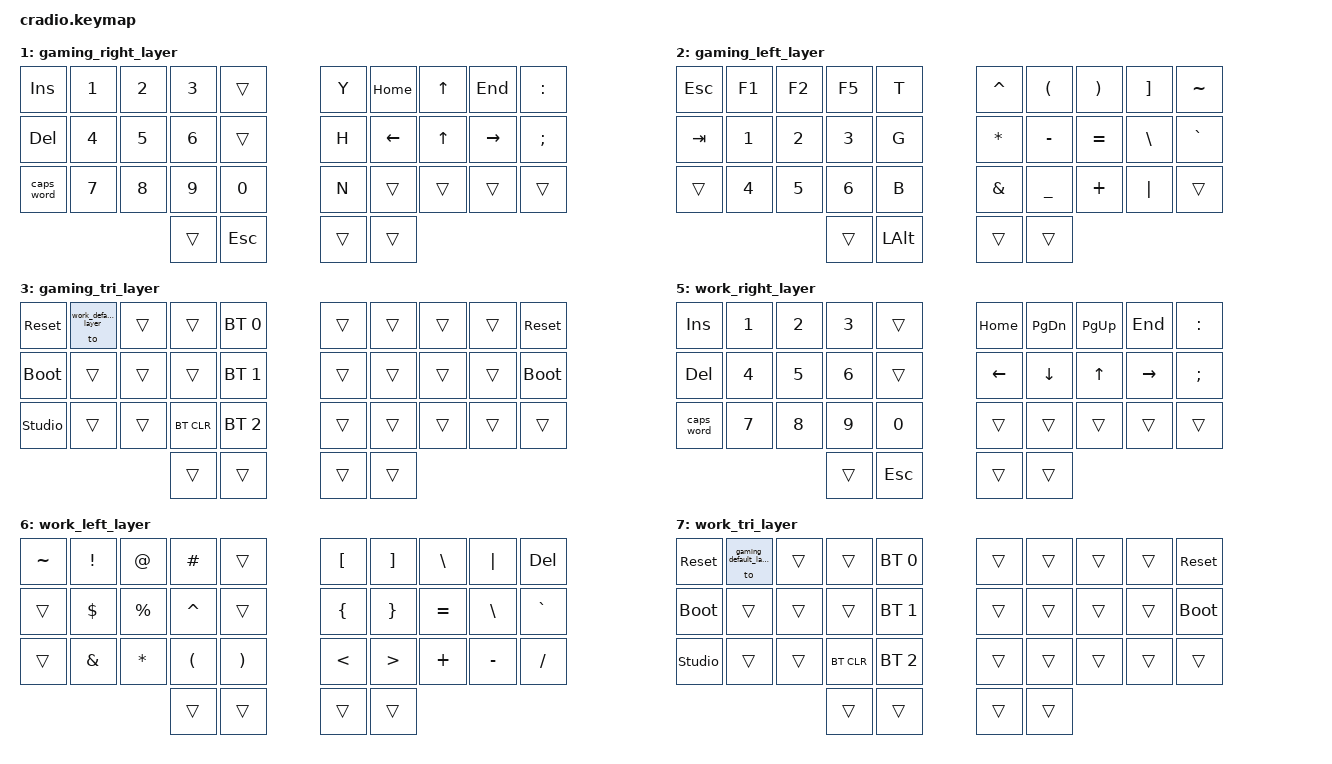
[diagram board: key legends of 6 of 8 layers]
// Copyright (c) 2022 The ZMK Contributors
// SPDX-License-Identifier: MIT

#include <behaviors.dtsi>
#include <dt-bindings/zmk/keys.h>
#include <dt-bindings/zmk/bt.h>

//defile layers for gaming and work
#define gaming_default_layer   0
#define gaming_right_layer     1
#define gaming_left_layer      2
#define gaming_tri_layer       3
#define work_default_layer     4
#define work_right_layer       5
#define work_left_layer        6
#define work_tri_layer         7

// Home row mods macro
#define HRML(k1,k2,k3,k4) &ht LSHFT k1  &ht LALT k2  &ht LCTRL k3  &ht LGUI k4
#define HRMR(k1,k2,k3,k4) &ht RGUI k1  &ht RCTRL k2  &ht RALT k3  &ht RSHFT k4

/ {
    behaviors {
        ht: hold_tap {
            compatible = "zmk,behavior-hold-tap";
            #binding-cells = <2>;
            flavor = "tap-preferred";
            tapping-term-ms = <220>;
            quick-tap-ms = <150>;
            require-prior-idle-ms = <100>;
            bindings = <&kp>, <&kp>;
        };
    };

    conditional_layers {
        compatible = "zmk,conditional-layers";
        gaming_tri_layer {
            if-layers = <gaming_right_layer gaming_left_layer>;
            then-layer = <gaming_tri_layer>;
        };
        work_tri_layer {
            if-layers = <work_right_layer work_left_layer>;
            then-layer = <work_tri_layer>;
        };
    };

    keymap {
        compatible = "zmk,keymap";
        gaming_default_layer {
            bindings = <
        //╭──────────┬──────────┬──────────┬──────────┬──────────╮   ╭──────────┬──────────┬──────────┬──────────┬──────────╮
        //│  tab     │  Q       │  W       │  E       │  R       │   │  Y       │  U       │  I       │  O       │  P       │
            &kp TAB   &kp Q      &kp W      &kp E      &kp R           &kp Y      &kp U      &kp I      &kp O      &kp P
        //├──────────┼──────────┼──────────┼──────────┼──────────┤   ├──────────┼──────────┼──────────┼──────────┼──────────┤
        //│  SHIFT   │    A     │  S       │  D       │  F       │   │  H       │  J       │  K       │  L       │ ' "      |
            &kp LSHFT   &kp  A     &kp S      &kp D     &kp F            &kp H      HRMR(J,        K,         L,        SQT)
        //├──────────┼──────────┼──────────┼──────────┼──────────┤   ├──────────┼──────────┼──────────┼──────────┼──────────┤
        //│  CTRL    │  Z       │  X       │ C        │  V       │   │  N       │  M       │ , <      │ . >      │ / ?      
            &kp RCTRL   &kp Z      &kp X      &kp C      &kp V           &kp N      &kp M   &kp COMMA   &kp DOT   &kp FSLH
        //╰──────────┴──────────┴──────────┼──────────┼──────────┤   ├──────────┼──────────┼──────────┴──────────┴──────────╯
                            &lt gaming_left_layer TAB   &kp SPACE     &kp ENTER  &lt gaming_right_layer BSPC
        //                                 ╰──────────┴──────────╯   ╰──────────┴──────────╯
            >;
        };

        gaming_right_layer {
            bindings = <
        //╭──────────┬──────────┬──────────┬──────────┬──────────╮   ╭──────────┬──────────┬──────────┬──────────┬──────────╮
        //│ INSERT   │  1       │  2       │  3       │          │   │ Y        │ HOME     │  UP      │ END      │  :       │
            &kp INS    &kp N1     &kp N2     &kp N3     &trans         &kp Y     &kp HOME    &kp UP     &kp END    &kp COLON
        //├──────────┼──────────┼──────────┼──────────┼──────────┤   ├──────────┼──────────┼──────────┼──────────┼──────────┤
        //│ DELETE   │  4       │  5       │  6       │          │   │ H        │ LEFT     │ DOWN     │ RIGHT    │  ;       │
            &kp DEL    &kp N4     &kp N5     &kp N6     &trans         &kp H      &kp LEFT   &kp UP     &kp RIGHT   &kp SEMI
        //├──────────┼──────────┼──────────┼──────────┼──────────┤   ├──────────┼──────────┼──────────┼──────────┼──────────┤
        //│ CAPS     │  7       │  8       │  9       │  0       │   │  N        │          │          │          │          │
           &caps_word  &kp N7     &kp N8     &kp N9     &kp N0         &kp N     &trans     &trans     &trans     &trans
        //╰──────────┴──────────┴──────────┼──────────┼──────────┤   ├──────────┼──────────┼──────────┴──────────┴──────────╯
                                             &trans     &kp ESC        &trans     &trans
        //                                 ╰──────────┴──────────╯   ╰──────────┴──────────╯
            >;
        };

        gaming_left_layer {
            bindings = <
        //╭──────────┬──────────┬──────────┬──────────┬──────────╮   ╭──────────┬──────────┬──────────┬──────────┬──────────╮
        //│     ESC  │  F1      │  F2      │  F5      │    T     │   │  ^       │  (       │  )       │  ]       │  ~       │
            &kp ESC     &kp F1     &kp F2    &kp F5      &kp T         &kp CARET  &kp LPAR   &kp RPAR   &kp RBKT   &kp TILDE
        //├──────────┼──────────┼──────────┼──────────┼──────────┤   ├──────────┼──────────┼──────────┼──────────┼──────────┤
        //│   tab    │  1       │  2       │  3       │  G       │   │  *       │  -       │  =       │  \       │  `       │
            &kp TAB     &kp N1     &kp N2     &kp N3      &kp G          &kp ASTRK  &kp MINUS  &kp EQUAL  &kp BSLH &kp GRAVE
        //├──────────┼──────────┼──────────┼──────────┼──────────┤   ├──────────┼──────────┼──────────┼──────────┼──────────┤
        //│          │    4     │   5      │    6     │   B      │   │  &       │  _       │  +       │  │       │          │
            &trans     &kp N4     &kp N5     &kp N6     &kp B         &kp AMPS   &kp UNDER  &kp PLUS   &kp PIPE   &trans
        //╰──────────┴──────────┴──────────┼──────────┼──────────┤   ├──────────┼──────────┼──────────┴──────────┴──────────╯
                                             &trans     &kp LALT        &trans     &trans
        //                                 ╰──────────┴──────────╯   ╰──────────┴──────────╯
            >;
        };

        gaming_tri_layer {
            bindings = <
        //╭──────────┬──────────┬──────────┬──────────┬──────────╮   ╭──────────┬──────────┬──────────┬──────────┬──────────╮
        //│ RESET    │          │          │          │PROFILE 0 │   │          │          │          │          │  RESET   │
           &sys_reset &to work_default_layer      &trans     &trans    &bt BT_SEL 0    &trans     &trans     &trans     &trans    &sys_reset
        //├──────────┼──────────┼──────────┼──────────┼──────────┤   ├──────────┼──────────┼──────────┼──────────┼──────────┤
        //│BOOTLOADER│          │          │          │PROFILE 1 │   │          │          │          │          │BOOTLOADER│
          &bootloader  &trans     &trans     &trans    &bt BT_SEL 1    &trans     &trans     &trans     &trans    &bootloader
        //├──────────┼──────────┼──────────┼──────────┼──────────┤   ├──────────┼──────────┼──────────┼──────────┼──────────┤
        //│          │          │          │ CLEAR BT │PROFILE 2 │   │          │          │          │          │          │
        &studio_unlock &trans     &trans    &bt BT_CLR &bt BT_SEL 2    &trans     &trans     &trans     &trans     &trans
        //╰──────────┴──────────┴──────────┼──────────┼──────────┤   ├──────────┼──────────┼──────────┴──────────┴──────────╯
                                             &trans     &trans         &trans     &trans
        //                                 ╰──────────┴──────────╯   ╰──────────┴──────────╯
            >;
        };
//////////////////////////////////////////////////////////////////////////////////////////////////////////////////////////////
        work_default_layer {
            bindings = <
        //╭──────────┬──────────┬──────────┬──────────┬──────────╮   ╭──────────┬──────────┬──────────┬──────────┬──────────╮
        //│  Q       │  W       │  E       │  R       │  T       │   │  Y       │  U       │  I       │  O       │  P       │
            &kp Q      &kp W      &kp E      &kp R      &kp T          &kp Y      &kp U      &kp I      &kp O      &kp P
        //├──────────┼──────────┼──────────┼──────────┼──────────┤   ├──────────┼──────────┼──────────┼──────────┼──────────┤
        //│  A       │  S       │  D       │  F       │  G       │   │  H       │  J       │  K       │  L       │ ' "      │
            HRML(A,        S,         D,         F)     &kp G          &kp H      HRMR(J,        K,         L,        SQT)
        //├──────────┼──────────┼──────────┼──────────┼──────────┤   ├──────────┼──────────┼──────────┼──────────┼──────────┤
        //│  Z       │  X       │  C       │  V       │  B       │   │  N       │  M       │ , <      │ . >      │ / ?      │
            &kp Z      &kp X      &kp C      &kp V      &kp B          &kp N      &kp M      &kp COMMA  &kp DOT    &kp FSLH
        //╰──────────┴──────────┴──────────┼──────────┼──────────┤   ├──────────┼──────────┼──────────┴──────────┴──────────╯
                                            &lt work_left_layer TAB   &kp ENTER     &kp SPACE  &lt work_right_layer BSPC
        //                                 ╰──────────┴──────────╯   ╰──────────┴──────────╯
            >;
        };

        work_right_layer {
            bindings = <
        //╭──────────┬──────────┬──────────┬──────────┬──────────╮   ╭──────────┬──────────┬──────────┬──────────┬──────────╮
        //│ INSERT   │  1       │  2       │  3       │          │   │ HOME     │ PAGE DN  │ PAGE UP  │ END      │  :       │
            &kp INS    &kp N1     &kp N2     &kp N3     &trans         &kp HOME   &kp PG_DN  &kp PG_UP  &kp END    &kp COLON
        //├──────────┼──────────┼──────────┼──────────┼──────────┤   ├──────────┼──────────┼──────────┼──────────┼──────────┤
        //│ DELETE   │  4       │  5       │  6       │          │   │ LEFT     │ DOWN     │ UP       │ RIGHT    │  ;       │
            &kp DEL    &kp N4     &kp N5     &kp N6     &trans         &kp LEFT   &kp DOWN   &kp UP   &kp RIGHT   &kp SEMI
        //├──────────┼──────────┼──────────┼──────────┼──────────┤   ├──────────┼──────────┼──────────┼──────────┼──────────┤
        //│ CAPS     │  7       │  8       │  9       │  0       │   │          │          │          │          │          │
           &caps_word  &kp N7     &kp N8     &kp N9     &kp N0         &trans     &trans     &trans     &trans     &trans
        //╰──────────┴──────────┴──────────┼──────────┼──────────┤   ├──────────┼──────────┼──────────┴──────────┴──────────╯
                                             &trans     &kp ESC        &trans     &trans
        //                                 ╰──────────┴──────────╯   ╰──────────┴──────────╯
            >;
        };


        work_left_layer {
            bindings = <
        //╭──────────┬──────────┬──────────┬──────────┬──────────╮   ╭──────────┬──────────┬──────────┬──────────┬──────────╮
        //│     ~    │  !       │  @       │  #       │          │   │  [       │  ]       │  \       │  |       │  DELETE       │
            &kp TILDE  &kp EXCL   &kp AT     &kp HASH   &trans         &kp LBKT  &kp RBKT   &kp BSLH   &kp PIPE   &kp DEL
        //├──────────┼──────────┼──────────┼──────────┼──────────┤   ├──────────┼──────────┼──────────┼──────────┼──────────┤
        //│          │  $       │  %       │  ^       │          │   │  {       │  }       │  =       │  \       │  `       │
            &trans     &kp DLLR  &kp PRCNT   &kp CARET   &trans        &kp LBRC   &kp RBRC   &kp EQUAL  &kp BSLH   &kp GRAVE
        //├──────────┼──────────┼──────────┼──────────┼──────────┤   ├──────────┼──────────┼──────────┼──────────┼──────────┤
        //│          │  &       │   *      │   (      │   )      │   │  <       │  >       │  +       │  -       │  / ?     │
            &trans     &kp AMPS  &kp ASTRK   &kp LPAR   &kp RPAR       &kp LT     &kp GT     &kp PLUS   &kp MINUS   &kp FSLH
        //╰──────────┴──────────┴──────────┼──────────┼──────────┤   ├──────────┼──────────┼──────────┴──────────┴──────────╯
                                             &trans     &trans         &trans     &trans
        //                                 ╰──────────┴──────────╯   ╰──────────┴──────────╯
            >;
        };

        // OLD code
        //work_left_layer {
        //    bindings = <
        //╭──────────┬──────────┬──────────┬──────────┬──────────╮   ╭──────────┬──────────┬──────────┬──────────┬──────────╮
        //│          │  [       │  {       │  }       │          │   │  ^       │  (       │  )       │  ]       │  ~       │
        //  &trans     &kp LBKT   &kp LBRC   &kp RBRC   &trans         &kp CARET  &kp LPAR   &kp RPAR   &kp RBKT   &kp TILDE
        //├──────────┼──────────┼──────────┼──────────┼──────────┤   ├──────────┼──────────┼──────────┼──────────┼──────────┤
        //│  !       │  @       │  #       │  $       │  %       │   │  *       │  -       │  =       │  \       │  `       │
        //  &kp EXCL   &kp AT     &kp HASH   &kp DLLR   &kp PRCNT      &kp ASTRK  &kp MINUS  &kp EQUAL  &kp BSLH   &kp GRAVE
        //├──────────┼──────────┼──────────┼──────────┼──────────┤   ├──────────┼──────────┼──────────┼──────────┼──────────┤
        //│          │          │          │          │          │   │  &       │  _       │  +       │  │       │          │
        //  &trans     &trans     &trans     &trans     &trans         &kp AMPS   &kp UNDER  &kp PLUS   &kp PIPE   &trans
        //╰──────────┴──────────┴──────────┼──────────┼──────────┤   ├──────────┼──────────┼──────────┴──────────┴──────────╯
        //                                     &trans     &trans         &trans     &trans
        //                                 ╰──────────┴──────────╯   ╰──────────┴──────────╯
        //    >;
        //};

        work_tri_layer {
            bindings = <
        //╭──────────┬──────────┬──────────┬──────────┬──────────╮   ╭──────────┬──────────┬──────────┬──────────┬──────────╮
        //│ RESET    │          │          │          │PROFILE 0 │   │          │          │          │          │  RESET   │
           &sys_reset  &to gaming_default_layer     &trans     &trans    &bt BT_SEL 0    &trans     &trans     &trans     &trans    &sys_reset
        //├──────────┼──────────┼──────────┼──────────┼──────────┤   ├──────────┼──────────┼──────────┼──────────┼──────────┤
        //│BOOTLOADER│          │          │          │PROFILE 1 │   │          │          │          │          │BOOTLOADER│
          &bootloader  &trans     &trans     &trans    &bt BT_SEL 1    &trans     &trans     &trans     &trans    &bootloader
        //├──────────┼──────────┼──────────┼──────────┼──────────┤   ├──────────┼──────────┼──────────┼──────────┼──────────┤
        //│          │          │          │ CLEAR BT │PROFILE 2 │   │          │          │          │          │          │
        &studio_unlock &trans     &trans    &bt BT_CLR &bt BT_SEL 2    &trans     &trans     &trans     &trans     &trans
        //╰──────────┴──────────┴──────────┼──────────┼──────────┤   ├──────────┼──────────┼──────────┴──────────┴──────────╯
                                             &trans     &trans         &trans     &trans
        //                                 ╰──────────┴──────────╯   ╰──────────┴──────────╯
            >;
        };

    };
};
